AUTOSAR XML (schema 00047)
# (C) 2021 HYUNDAI AUTOEVER Corp.
package /Svc_ComM/ClientServerInterface
  4 x client server interface, all with is-service=true, service-kind=COM-MANAGER:
    ComM_ChannelLimitation
      operation GetInhibitionStatus: possible-error=[ComM_ChannelLimitation/E_NOT_OK, ComM_ChannelLimitation/E_OK]
        arg Status: type=ComM_InhibitionStatusType, direction=OUT
      operation LimitChannelToNoComMode: possible-error=[ComM_ChannelLimitation/E_NOT_OK, ComM_ChannelLimitation/E_OK]
        arg Status: type=boolean, direction=IN
      error E_NOT_OK: error-code=1
      error E_OK: error-code=0
    ComM_ChannelWakeup
      operation GetInhibitionStatus: possible-error=[ComM_ChannelWakeup/E_NOT_OK, ComM_ChannelWakeup/E_OK]
        arg Status: type=ComM_InhibitionStatusType, direction=OUT
      operation PreventWakeUp: possible-error=[ComM_ChannelWakeup/E_NOT_OK, ComM_ChannelWakeup/E_OK]
        arg Status: type=boolean, direction=IN
      error E_NOT_OK: error-code=1
      error E_OK: error-code=0
    ComM_ECUModeLimitation
      operation LimitECUToNoComMode: possible-error=[ComM_ECUModeLimitation/E_NOT_OK, ComM_ECUModeLimitation/E_OK]
        arg Status: type=boolean, direction=IN
      operation SetECUGroupClassification: possible-error=[ComM_ECUModeLimitation/E_NOT_OK, ComM_ECUModeLimitation/E_OK]
        arg Status: type=ComM_InhibitionStatusType, direction=IN
      error E_NOT_OK: error-code=1
      error E_OK: error-code=0
    ComM_UserRequest
      4 x operation:
        GetCurrentComMode: possible-error=[ComM_UserRequest/E_NOT_OK, ComM_UserRequest/E_OK]
          arg ComMode: type=ComM_ModeType, direction=OUT
        GetMaxComMode: possible-error=[ComM_UserRequest/E_NOT_OK, ComM_UserRequest/E_OK]
          arg ComMode: type=ComM_ModeType, direction=OUT
        GetRequestedComMode: possible-error=[ComM_UserRequest/E_NOT_OK, ComM_UserRequest/E_OK]
          arg ComMode: type=ComM_ModeType, direction=OUT
        RequestComMode: possible-error=[E_MODE_LIMITATION, ComM_UserRequest/E_NOT_OK, ComM_UserRequest/E_OK]
          arg ComMode: type=ComM_ModeType, direction=IN
      error E_MODE_LIMITATION: error-code=2
      error E_NOT_OK: error-code=1
      error E_OK: error-code=0
package /Svc_ComM/DataTypeMappingSet
  data type mapping set ComMModeDataTypeMappingSet: mode-request-type-map{implementation-data-type=ComM_ModeType, mode-group=ComMMode}
package /Svc_ComM/ImplementationDataTypes
  11 x impl type:
    ComM_ConfigType: category=STRUCTURE, type-emitter=ComM.h
      element dummy: category=VALUE, base-type=uint8
    ComM_InhibitionStatusType: range raw 1..2, implementation-data-type=uint8
    ComM_InitStatusType: compu {0x00=COMM_UNINIT, 0x01=COMM_INIT}, range raw 0..1, implementation-data-type=uint8, type-emitter=ComM.h
    ComM_ModeType: compu {0=COMM_NO_COMMUNICATION, 1=COMM_SILENT_COMMUNICATION, 2=COMM_FULL_COMMUNICATION}, range raw 0..2, implementation-data-type=uint8
    ComM_PncModeType: compu {0x00=COMM_PNC_REQUESTED, 0x01=COMM_PNC_READY_SLEEP, 0x02=COMM_PNC_PREPARE_SLEEP, 0x03=COMM_PNC_NO_COMMUNICATION}, range raw 0, implementation-data-type=uint8, type-emitter=ComM.h
    ComM_StateType: range raw 0..4, implementation-data-type=uint8, type-emitter=ComM.h
    ComM_UserHandleArrayType_ComMChannel_LIN1: category=STRUCTURE
      element numberOfRequesters: category=VALUE, base-type=uint8
      element handleArray: implementation-data-type=ComM_UserHandleSubArrayType_ComMChannel_LIN1
    ComM_UserHandleArrayType_ComMChannel_LIN2: category=STRUCTURE
      element numberOfRequesters: category=VALUE, base-type=uint8
      element handleArray: implementation-data-type=ComM_UserHandleSubArrayType_ComMChannel_LIN2
    ComM_UserHandleSubArrayType_ComMChannel_LIN1: category=ARRAY
      element UserHandleSubArray_ComMChannel_LIN1: array-size=1, array-size-semantics=FIXED-SIZE, implementation-data-type=ComM_UserHandleType
    ComM_UserHandleSubArrayType_ComMChannel_LIN2: category=ARRAY
      element UserHandleSubArray_ComMChannel_LIN2: array-size=1, array-size-semantics=FIXED-SIZE, implementation-data-type=ComM_UserHandleType
    ComM_UserHandleType: category=VALUE, base-type=uint8, range raw 0..254
package /Svc_ComM/ModeDeclarationGroups
  mode declaration group ComMMode: category=EXPLICIT_ORDER, initial-mode=COMM_NO_COMMUNICATION, on-transition-value=255
    mode COMM_FULL_COMMUNICATION: category=EXPLICIT_ORDER, value=2
    mode COMM_NO_COMMUNICATION: category=EXPLICIT_ORDER, value=0
    mode COMM_SILENT_COMMUNICATION: category=EXPLICIT_ORDER, value=1
package /Svc_ComM/ModeSwitchInterface
  mode switch interface ComM_CurrentMode: is-service=true, service-kind=COM-MANAGER
    mode group currentMode: type=ComMMode
package /Svc_ComM/ServiceSwComponentType
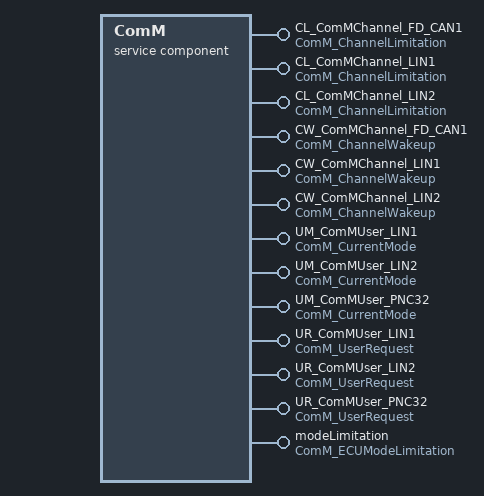
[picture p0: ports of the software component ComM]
  service sw component type ComM
    13 x provide port:
      CL_ComMChannel_FD_CAN1: provided-interface=ComM_ChannelLimitation
        provided-com-specs:
          operation=ComM_ChannelLimitation/GetInhibitionStatus, queue-length=1
          operation=LimitChannelToNoComMode, queue-length=1
      CL_ComMChannel_LIN1: provided-interface=ComM_ChannelLimitation
        provided-com-specs:
          operation=ComM_ChannelLimitation/GetInhibitionStatus, queue-length=1
          operation=LimitChannelToNoComMode, queue-length=1
      CL_ComMChannel_LIN2: provided-interface=ComM_ChannelLimitation
        provided-com-specs:
          operation=ComM_ChannelLimitation/GetInhibitionStatus, queue-length=1
          operation=LimitChannelToNoComMode, queue-length=1
      CW_ComMChannel_FD_CAN1: provided-interface=ComM_ChannelWakeup
        provided-com-specs:
          operation=ComM_ChannelWakeup/GetInhibitionStatus, queue-length=1
          operation=PreventWakeUp, queue-length=1
      CW_ComMChannel_LIN1: provided-interface=ComM_ChannelWakeup
        provided-com-specs:
          operation=ComM_ChannelWakeup/GetInhibitionStatus, queue-length=1
          operation=PreventWakeUp, queue-length=1
      CW_ComMChannel_LIN2: provided-interface=ComM_ChannelWakeup
        provided-com-specs:
          operation=ComM_ChannelWakeup/GetInhibitionStatus, queue-length=1
          operation=PreventWakeUp, queue-length=1
      UM_ComMUser_LIN1: mode-switch-sender-com-spec{enhanced-mode-api=false, mode-group=currentMode, queue-length=1}, provided-interface=ComM_CurrentMode
      UM_ComMUser_LIN2: mode-switch-sender-com-spec{enhanced-mode-api=false, mode-group=currentMode, queue-length=1}, provided-interface=ComM_CurrentMode
      UM_ComMUser_PNC32: mode-switch-sender-com-spec{enhanced-mode-api=false, mode-group=currentMode, queue-length=1}, provided-interface=ComM_CurrentMode
      UR_ComMUser_LIN1: provided-interface=ComM_UserRequest
        provided-com-specs:
          operation=GetCurrentComMode, queue-length=1
          operation=GetMaxComMode, queue-length=1
          operation=GetRequestedComMode, queue-length=1
          operation=RequestComMode, queue-length=1
      UR_ComMUser_LIN2: provided-interface=ComM_UserRequest
        provided-com-specs:
          operation=GetCurrentComMode, queue-length=1
          operation=GetMaxComMode, queue-length=1
          operation=GetRequestedComMode, queue-length=1
          operation=RequestComMode, queue-length=1
      UR_ComMUser_PNC32: provided-interface=ComM_UserRequest
        provided-com-specs:
          operation=GetCurrentComMode, queue-length=1
          operation=GetMaxComMode, queue-length=1
          operation=GetRequestedComMode, queue-length=1
          operation=RequestComMode, queue-length=1
      modeLimitation: provided-com-specs=[{operation=LimitECUToNoComMode, queue-length=1}, {operation=SetECUGroupClassification, queue-length=1}], provided-interface=ComM_ECUModeLimitation
    behavior SwcIB_ComM: data-type-mapping=ComMModeDataTypeMappingSet, handle-termination-and-restart=NO-SUPPORT
      23 x operation invoked event:
        OIE_GetCurrentComMode_ComMUser_LIN1: start-on-event=GetCurrentComMode, operation=UR_ComMUser_LIN1.GetCurrentComMode
        OIE_GetCurrentComMode_ComMUser_LIN2: start-on-event=GetCurrentComMode, operation=UR_ComMUser_LIN2.GetCurrentComMode
        OIE_GetCurrentComMode_ComMUser_PNC32: start-on-event=GetCurrentComMode, operation=UR_ComMUser_PNC32.GetCurrentComMode
        OIE_GetInhibitionStatus_ComMChannel_FD_CAN1: start-on-event=GetInhibitionStatus, operation=CL_ComMChannel_FD_CAN1.GetInhibitionStatus
        OIE_GetInhibitionStatus_ComMChannel_LIN1: start-on-event=GetInhibitionStatus, operation=CL_ComMChannel_LIN1.GetInhibitionStatus
        OIE_GetInhibitionStatus_ComMChannel_LIN2: start-on-event=GetInhibitionStatus, operation=CL_ComMChannel_LIN2.GetInhibitionStatus
        OIE_GetMaxComMode_ComMUser_LIN1: start-on-event=GetMaxComMode, operation=UR_ComMUser_LIN1.GetMaxComMode
        OIE_GetMaxComMode_ComMUser_LIN2: start-on-event=GetMaxComMode, operation=UR_ComMUser_LIN2.GetMaxComMode
        OIE_GetMaxComMode_ComMUser_PNC32: start-on-event=GetMaxComMode, operation=UR_ComMUser_PNC32.GetMaxComMode
        OIE_GetRequestedComMode_ComMUser_LIN1: start-on-event=GetRequestedComMode, operation=UR_ComMUser_LIN1.GetRequestedComMode
        OIE_GetRequestedComMode_ComMUser_LIN2: start-on-event=GetRequestedComMode, operation=UR_ComMUser_LIN2.GetRequestedComMode
        OIE_GetRequestedComMode_ComMUser_PNC32: start-on-event=GetRequestedComMode, operation=UR_ComMUser_PNC32.GetRequestedComMode
        OIE_LimitChannelToNoComMode_ComMChannel_FD_CAN1: start-on-event=LimitChannelToNoComMode, operation=CL_ComMChannel_FD_CAN1.LimitChannelToNoComMode
        OIE_LimitChannelToNoComMode_ComMChannel_LIN1: start-on-event=LimitChannelToNoComMode, operation=CL_ComMChannel_LIN1.LimitChannelToNoComMode
        OIE_LimitChannelToNoComMode_ComMChannel_LIN2: start-on-event=LimitChannelToNoComMode, operation=CL_ComMChannel_LIN2.LimitChannelToNoComMode
        OIE_LimitECUToNoComMode: start-on-event=LimitECUToNoComMode, operation=modeLimitation.LimitECUToNoComMode
        OIE_PreventWakeUp_ComMChannel_FD_CAN1: start-on-event=PreventWakeUp, operation=CW_ComMChannel_FD_CAN1.PreventWakeUp
        OIE_PreventWakeUp_ComMChannel_LIN1: start-on-event=PreventWakeUp, operation=CW_ComMChannel_LIN1.PreventWakeUp
        OIE_PreventWakeUp_ComMChannel_LIN2: start-on-event=PreventWakeUp, operation=CW_ComMChannel_LIN2.PreventWakeUp
        OIE_RequestComMode_ComMUser_LIN1: start-on-event=RequestComMode, operation=UR_ComMUser_LIN1.RequestComMode
        OIE_RequestComMode_ComMUser_LIN2: start-on-event=RequestComMode, operation=UR_ComMUser_LIN2.RequestComMode
        OIE_RequestComMode_ComMUser_PNC32: start-on-event=RequestComMode, operation=UR_ComMUser_PNC32.RequestComMode
        OIE_SetECUGroupClassification: start-on-event=SetECUGroupClassification, operation=modeLimitation.SetECUGroupClassification
      port-api-options:
        enable-take-address=true, indirect-api=false, port=modeLimitation
        {enable-take-address=true, indirect-api=false, port-defined-argument-value{value=0, value-type=NetworkHandleType}, port=CL_ComMChannel_FD_CAN1}
        {enable-take-address=true, indirect-api=false, port-defined-argument-value{value=1, value-type=NetworkHandleType}, port=CL_ComMChannel_LIN1}
        {enable-take-address=true, indirect-api=false, port-defined-argument-value{value=2, value-type=NetworkHandleType}, port=CL_ComMChannel_LIN2}
        {enable-take-address=true, indirect-api=false, port-defined-argument-value{value=0, value-type=ComM_UserHandleType}, port=UR_ComMUser_LIN1}
        enable-take-address=true, indirect-api=false, port=UM_ComMUser_LIN1
        {enable-take-address=true, indirect-api=false, port-defined-argument-value{value=2, value-type=ComM_UserHandleType}, port=UR_ComMUser_PNC32}
        enable-take-address=true, indirect-api=false, port=UM_ComMUser_PNC32
        {enable-take-address=true, indirect-api=false, port-defined-argument-value{value=1, value-type=ComM_UserHandleType}, port=UR_ComMUser_LIN2}
        enable-take-address=true, indirect-api=false, port=UM_ComMUser_LIN2
        {enable-take-address=true, indirect-api=false, port-defined-argument-value{value=0, value-type=NetworkHandleType}, port=CW_ComMChannel_FD_CAN1}
        {enable-take-address=true, indirect-api=false, port-defined-argument-value{value=1, value-type=NetworkHandleType}, port=CW_ComMChannel_LIN1}
        {enable-take-address=true, indirect-api=false, port-defined-argument-value{value=2, value-type=NetworkHandleType}, port=CW_ComMChannel_LIN2}
      9 x runnable:
        GetCurrentComMode: arguments=[symbol=User, symbol=ComMode], can-be-invoked-concurrently=true, symbol=ComM_GetCurrentComMode
          mode switch point ModeSwitchPoint_CurrentMode_UM_ComMUser_LIN1: mode-group=UM_ComMUser_LIN1.currentMode
          mode switch point ModeSwitchPoint_CurrentMode_UM_ComMUser_LIN2: mode-group=UM_ComMUser_LIN2.currentMode
          mode switch point ModeSwitchPoint_CurrentMode_UM_ComMUser_PNC32: mode-group=UM_ComMUser_PNC32.currentMode
        GetInhibitionStatus: arguments=[symbol=Channel, symbol=Status], symbol=ComM_GetInhibitionStatus
        GetMaxComMode: arguments=[symbol=User, symbol=ComMode], can-be-invoked-concurrently=true, symbol=ComM_GetMaxComMode
        GetRequestedComMode: arguments=[symbol=User, symbol=ComMode], can-be-invoked-concurrently=true, symbol=ComM_GetRequestedComMode
        LimitChannelToNoComMode: arguments=[symbol=Channel, symbol=Status], symbol=ComM_LimitChannelToNoComMode
        LimitECUToNoComMode: runnable-entity-argument=symbol=Status, symbol=ComM_LimitECUToNoComMode
        PreventWakeUp: arguments=[symbol=Channel, symbol=Status], symbol=ComM_PreventWakeUp
        RequestComMode: arguments=[symbol=User, symbol=ComMode], can-be-invoked-concurrently=true, symbol=ComM_RequestComMode
        SetECUGroupClassification: runnable-entity-argument=symbol=Status, symbol=ComM_SetECUGroupClassification
  swc implementation SwcImplementation_ComM: swc-bsw-mapping=SwcBswMapping_ComM, behavior=SwcIB_ComM
